# EDMA3CC register map
Vendor: Texas Instruments
Peripheral module from a debugger description file (folder am437x).
Registers are 32-bit, access per field, no defined reset value unless marked. A register's access mark holds for its fields unless they carry their own. Offsets are as the file gives them; lines under a group give offsets from that group; [hi:lo] are bit positions; {n}, {i} and the like mark numbered series; 'fields as' and 'values as' point back to an identical list; <NAME> marks a mode.

## EDMA3CC (part 1 of 3)
0x800 MPFAR ro — A CPU write of 1 to the MPFCLR bit in the memory protection fault command register (MPFCR) causes any error conditions stored in MPFAR to be cleared.
  [31:0] FADDR — Fault address. [[br]]This 32 bit read-only status register contains the fault address when a memory protection violation is detected. [[br]]This register can only be cleared via the memory protection fault command register (MPFCR). [[br]]Value 0 to FFFF FFFFh.
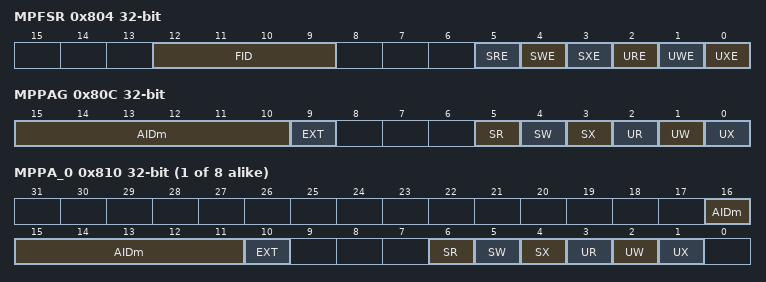
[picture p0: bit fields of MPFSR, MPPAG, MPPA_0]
0x804 MPFSR ro — A CPU write of 1 to the MPFCLR bit in the memory protection fault command register (MPFCR) causes any error conditions stored in MPFSR to be cleared.
  [12:9] FID — Faulted identification. [[br]]FID contains valid information if any of the MP error bits (UXE, UWE, URE, SXE, SWE, SRE) are nonzero (that is, if an error has been detected.) The FID field contains the privilege ID for the specific request/requestor that resulted in an MP error. [[br]]Value 0 to Fh.
  [5] SRE — Supervisor read error.
    1=en_2_0x1 (Supervisor level task attempted to read from a MP page without SR permissions.); 0=en_1_0x0 (No error detected.)
  [4] SWE — Supervisor write error.
    1=en_2_0x1 (Supervisor level task attempted to write to a MP page without SW permissions.); 0=en_1_0x0 (No error detected.)
  [3] SXE — Supervisor execute error.
    1=en_2_0x1 (Supervisor level task attempted to execute from a MP page without SX permissions.); 0=en_1_0x0 (No error detected.)
  [2] URE — User read error.
    1=en_2_0x1 (User level task attempted to read from a MP page without UR permissions.); 0=en_1_0x0 (No error detected.)
  [1] UWE — User write error.
    1=en_2_0x1 (User level task attempted to write to a MP page without UW permissions.); 0=en_1_0x0 (No error detected.)
  [0] UXE — User execute error.
    1=en_2_0x1 (User level task attempted to execute from a MP page without UX permissions.); 0=en_1_0x0 (No error detected.)
0x808 MPFCR
  [0] MPFCLR wo — Fault clear register.
    1=en_2_0x1 (CPU write of 1 to the MPFCLR bit causes any error conditions stored in the memory protection fault address register (MPFAR) and the memory protection fault status register (MPFSR) to be cleared.); 0=en_1_0x0 (CPU write of 0 has no effect.)
0x80C MPPAG
  [15:10] AIDm rw — Allowed ID 'N'
    1=en_2_0x1 (Requests with Privilege ID == N are permitted, if access type is allowed as defined by permission settings (UW, UR, SW, SR).); 0=en_1_0x0 (Requests with Privilege ID == N are not allowed to region M, regardless of permission settings (UW, UR, SW, SR).)
  [9] EXT rw — External Allowed ID.
    1=en_2_0x1 (Requests with Privilege ID >= 6 are permitted, if access type is allowed as defined by permission settings (UW, UR, SW, SR).); 0=en_1_0x0 (Requests with Privilege ID >= 6 are not allowed to region M, regardless of permission settings (UW, UR, SW, SR).)
  [5] SR rw — Supervisor read permission.
    1=en_2_0x1 (Supervisor write accesses are allowed from region M addresses.); 0=en_1_0x0 (Supervisor read accesses are not allowed from region M.)
  [4] SW rw — Supervisor write permission.
    1=en_2_0x1 (Supervisor write accesses are allowed to region N addresses.); 0=en_1_0x0 (Supervisor write accesses are not allowed to region M.)
  [3] SX rw — Supervisor execute permission.
    1=en_2_0x1 (Supervisor execute accesses are allowed from region M addresses.); 0=en_1_0x0 (Supervisor execute accesses are not allowed from region M.)
  [2] UR rw — User read permission.
    1=en_2_0x1 (User read accesses are allowed from region N addresses.); 0=en_1_0x0 (User read accesses are not allowed from region M.)
  [1] UW rw — User write permission.
    1=en_2_0x1 (User write accesses are allowed to region M addresses.); 0=en_1_0x0 (User write accesses are not allowed to region M.)
  [0] UX rw — User execute permission.
    1=en_2_0x1 (User execute accesses are allowed from region M addresses.); 0=en_1_0x0 (User execute accesses are not allowed from region M.)
{0x810+4i} MPPA_{i} (i=0..7)
  [16:11] AIDm rw — Allowed ID 'N'
    values as MPPAG.AIDm
  [10] EXT rw — External Allowed ID.
    values as MPPAG.EXT
  [6] SR rw — Supervisor read permission.
    values as MPPAG.SR
  [5] SW rw — Supervisor write permission.
    values as MPPAG.SW
  [4] SX rw — Supervisor execute permission.
    values as MPPAG.SX
  [3] UR rw — User read permission.
    values as MPPAG.UR
  [2] UW rw — User write permission.
    values as MPPAG.UW
  [1] UX rw — User execute permission.
    values as MPPAG.UX
0x1000 ER ro — All external events are captured in the event register (ER/ERH). The events are latched even when the events are not enabled. If the event bit corresponding to the latched event is enabled (EER.En/EERH.En = 1), then the event is evaluated by the EDMA3CC logic for an associated transfer request submission to the transfer controllers. The event register bits are automatically cleared (ER.En/ERH.En= 0) once the corresponding events are prioritized and serviced. If ER.En/ERH.En are already set and another event is received on the same channel/event, then the corresponding event is latched in the event miss register (EMR.En/EMRH.En), provided that the event was enabled (EER.En/EERH.En = 1). Event n can be cleared by the CPU writing a 1 to corresponding event bit in the event clear register (ECR/ECRH). The setting of an event is a higher priority relative to clear operations (via hardware or software). If set and clear conditions occur concurrently, the set condition wins. If the event was previously set, then EMR/EMRH would be set because an event is lost. If the event was previously clear, then the event remains set and is prioritized for submission to the event queues. The Debug List table provides the type of synchronization events and the EDMA3CC channels associated to each of these external events. This register is part of a set of registers that pertain to the 64 DMA channels. The 64 DMA channels consist of a set of registers (with exception of DMAQNUMn) that each have 64 bits and the bit position of each register matches the DMA channel number. Each register is named with the format reg_name that corresponds to DMA channels 0 through 31 and reg_name_High that corresponds to DMA channels 32 through 64. For example, the event register (ER) corresponds to DMA channel 0 through 31 and the event register high register (ERH) corresponds to DMA channel 32 through 63. The register is typically called the event register. The DMA channel registers are accessible via read/writes to the global address range. They are also accessible via read/writes to the shadow address range. The read/write ability to the registers in the shadow region are controlled by the DMA region access registers (DRAEm/DRAEHm).
  [31:0] En — Event 0 to 31. [[br]]Events 0 to 31 are captured by the EDMA3CC and are latched into ER. [[br]]The events are set (En = 1) even when events are disabled (En = 0 in the event enable register, EER). [[br]]
    1=en_2_0x1 (EDMA3CC event is asserted. Corresponding DMA event is prioritized versus other pending DMA/QDMA events for submission to the EDMA3TC.); 0=en_1_0x0 (EDMA3CC event is not asserted.)
0x1004 ERH ro — All external events are captured in the event register (ER/ERH). The events are latched even when the events are not enabled. If the event bit corresponding to the latched event is enabled (EER.En/EERH.En = 1), then the event is evaluated by the EDMA3CC logic for an associated transfer request submission to the transfer controllers. The event register bits are automatically cleared (ER.En/ERH.En= 0) once the corresponding events are prioritized and serviced. If ER.En/ERH.En are already set and another event is received on the same channel/event, then the corresponding event is latched in the event miss register (EMR.En/EMRH.En), provided that the event was enabled (EER.En/EERH.En = 1). Event n can be cleared by the CPU writing a 1 to corresponding event bit in the event clear register (ECR/ECRH). The setting of an event is a higher priority relative to clear operations (via hardware or software). If set and clear conditions occur concurrently, the set condition wins. If the event was previously set, then EMR/EMRH would be set because an event is lost. If the event was previously clear, then the event remains set and is prioritized for submission to the event queues. The Debug List table provides the type of synchronization events and the EDMA3CC channels associated to each of these external events. This register is part of a set of registers that pertain to the 64 DMA channels. The 64 DMA channels consist of a set of registers (with exception of DMAQNUMn) that each have 64 bits and the bit position of each register matches the DMA channel number. Each register is named with the format reg_name that corresponds to DMA channels 0 through 31 and reg_name_High that corresponds to DMA channels 32 through 64. For example, the event register (ER) corresponds to DMA channel 0 through 31 and the event register high register (ERH) corresponds to DMA channel 32 through 63. The register is typically called the event register. The DMA channel registers are accessible via read/writes to the global address range. They are also accessible via read/writes to the shadow address range. The read/write ability to the registers in the shadow region are controlled by the DMA region access registers (DRAEm/DRAEHm).
  [31:0] En — Event 32 to 63. [[br]]Events 32 to 63 are captured by the EDMA3CC and are latched into ERH. [[br]]The events are set (En = 1) even when events are disabled (En = 0 in the event enable register high, EERH). [[br]]
    values as ER.En
0x1008 ECR wo — Once an event has been posted in the event registers (ER/ERH), the event is cleared in two ways. If the event is enabled in the event enable register (EER/EERH) and the EDMA3CC submits a transfer request for the event to the EDMA3TC, it clears the corresponding event bit in the event register. If the event is disabled in the event enable register (EER/EERH), the CPU can clear the event by way of the event clear registers (ECR/ECRH). Writing a 1 to any of the bits clears the corresponding event; writing a 0 has no effect. Once an event bit is set in the event register, it remains set until EDMA3CC submits a transfer request for that event or the CPU clears the event by setting the corresponding bit in ECR/ECRH. This register is part of a set of registers that pertain to the 64 DMA channels. The 64 DMA channels consist of a set of registers (with exception of DMAQNUMn) that each have 64 bits and the bit position of each register matches the DMA channel number. Each register is named with the format reg_name that corresponds to DMA channels 0 through 31 and reg_name_High that corresponds to DMA channels 32 through 64. For example, the event register (ER) corresponds to DMA channel 0 through 31 and the event register high register (ERH) corresponds to DMA channel 32 through 63. The register is typically called the event register. The DMA channel registers are accessible via read/writes to the global address range. They are also accessible via read/writes to the shadow address range. The read/write ability to the registers in the shadow region are controlled by the DMA region access registers (DRAEm/DRAEHm).
  [31:0] En — Event clear for event 0 to 31. [[br]]Any of the event bits in ECR is set to clear the event (En) in the event register (ER). [[br]]A write of 0 has no effect. [[br]]
    1=en_2_0x1 (EDMA3CC event is cleared in the event register (ER).); 0=en_1_0x0 (No effect.)
0x100C ECRH wo — Once an event has been posted in the event registers (ER/ERH), the event is cleared in two ways. If the event is enabled in the event enable register (EER/EERH) and the EDMA3CC submits a transfer request for the event to the EDMA3TC, it clears the corresponding event bit in the event register. If the event is disabled in the event enable register (EER/EERH), the CPU can clear the event by way of the event clear registers (ECR/ECRH). Writing a 1 to any of the bits clears the corresponding event; writing a 0 has no effect. Once an event bit is set in the event register, it remains set until EDMA3CC submits a transfer request for that event or the CPU clears the event by setting the corresponding bit in ECR/ECRH. This register is part of a set of registers that pertain to the 64 DMA channels. The 64 DMA channels consist of a set of registers (with exception of DMAQNUMn) that each have 64 bits and the bit position of each register matches the DMA channel number. Each register is named with the format reg_name that corresponds to DMA channels 0 through 31 and reg_name_High that corresponds to DMA channels 32 through 64. For example, the event register (ER) corresponds to DMA channel 0 through 31 and the event register high register (ERH) corresponds to DMA channel 32 through 63. The register is typically called the event register. The DMA channel registers are accessible via read/writes to the global address range. They are also accessible via read/writes to the shadow address range. The read/write ability to the registers in the shadow region are controlled by the DMA region access registers (DRAEm/DRAEHm).
  [31:0] En — Event clear for event 32 to 63. [[br]]Any of the event bits in ECRH are set to clear the event (En) in the event register high (ERH). [[br]]A write of 0 has no effect. [[br]]
    1=en_2_0x1 (EDMA3CC event is cleared in the event register high (ERH).); 0=en_1_0x0 (No effect.)
0x1010 ESR rw — The event set registers (ESR/ESRH) allow the CPU (EDMA3 programmers) to manually set events to initiate DMA transfer requests. CPU writes of 1 to any event set register (En) bits set the corresponding bits in the registers. The set event is evaluated by the EDMA3CC logic for an associated transfer request submission to the transfer controllers. Writing a 0 has no effect. The event set registers operate independent of the event registers (ER/ERH), and a write of 1 is always considered a valid event regardless of whether the event is enabled (the corresponding event bits are set or cleared in EER.En/EERH.En). Once the event is set in the event set registers, it cannot be cleared by CPU writes, in other words, the event clear registers (ECR/ECRH) have no effect on the state of ESR/ESRH. The bits will only be cleared once the transfer request corresponding to the event has been submitted to the transfer controller. The setting of an event is a higher priority relative to clear operations (via hardware). If set and clear conditions occur concurrently, the set condition wins. If the event was previously set, then EMR/EMRH would be set because an event is lost. If the event was previously clear, then the event remains set and is prioritized for submission to the event queues. Manually-triggered transfers via writes to ESR/ESRH allow the CPU to submit DMA requests in the system, these are relevant for memory-to-memory transfer scenarios. If the ESR.En/ESRH.En bit is already set and another CPU write of 1 is attempted to the same bit, then the corresponding event is latched in the event missed registers (EMR.En/EMRH.En = 1). This register is part of a set of registers that pertain to the 64 DMA channels. The 64 DMA channels consist of a set of registers (with exception of DMAQNUMn) that each have 64 bits and the bit position of each register matches the DMA channel number. Each register is named with the format reg_name that corresponds to DMA channels 0 through 31 and reg_name_High that corresponds to DMA channels 32 through 64. For example, the event register (ER) corresponds to DMA channel 0 through 31 and the event register high register (ERH) corresponds to DMA channel 32 through 63. The register is typically called the event register. The DMA channel registers are accessible via read/writes to the global address range. They are also accessible via read/writes to the shadow address range. The read/write ability to the registers in the shadow region are controlled by the DMA region access registers (DRAEm/DRAEHm).
  [31:0] En — Event set for event 0 to 31.
    1=en_2_0x1 (Corresponding DMA event is prioritized versus other pending DMA/QDMA events for submission to the EDMA3TC.); 0=en_1_0x0 (No effect.)
0x1014 ESRH rw — The event set registers (ESR/ESRH) allow the CPU (EDMA3 programmers) to manually set events to initiate DMA transfer requests. CPU writes of 1 to any event set register (En) bits set the corresponding bits in the registers. The set event is evaluated by the EDMA3CC logic for an associated transfer request submission to the transfer controllers. Writing a 0 has no effect. The event set registers operate independent of the event registers (ER/ERH), and a write of 1 is always considered a valid event regardless of whether the event is enabled (the corresponding event bits are set or cleared in EER.En/EERH.En). Once the event is set in the event set registers, it cannot be cleared by CPU writes, in other words, the event clear registers (ECR/ECRH) have no effect on the state of ESR/ESRH. The bits will only be cleared once the transfer request corresponding to the event has been submitted to the transfer controller. The setting of an event is a higher priority relative to clear operations (via hardware). If set and clear conditions occur concurrently, the set condition wins. If the event was previously set, then EMR/EMRH would be set because an event is lost. If the event was previously clear, then the event remains set and is prioritized for submission to the event queues. Manually-triggered transfers via writes to ESR/ESRH allow the CPU to submit DMA requests in the system, these are relevant for memory-to-memory transfer scenarios. If the ESR.En/ESRH.En bit is already set and another CPU write of 1 is attempted to the same bit, then the corresponding event is latched in the event missed registers (EMR.En/EMRH.En = 1). This register is part of a set of registers that pertain to the 64 DMA channels. The 64 DMA channels consist of a set of registers (with exception of DMAQNUMn) that each have 64 bits and the bit position of each register matches the DMA channel number. Each register is named with the format reg_name that corresponds to DMA channels 0 through 31 and reg_name_High that corresponds to DMA channels 32 through 64. For example, the event register (ER) corresponds to DMA channel 0 through 31 and the event register high register (ERH) corresponds to DMA channel 32 through 63. The register is typically called the event register. The DMA channel registers are accessible via read/writes to the global address range. They are also accessible via read/writes to the shadow address range. The read/write ability to the registers in the shadow region are controlled by the DMA region access registers (DRAEm/DRAEHm).
  [31:0] En — Event set for event 32 to 63.
    values as ESR.En
0x1018 CER ro — When the OPTIONS parameter for a PaRAM entry is programmed to returned a chained completion code (ITCCHEN = 1 and/or TCCHEN = 1), then the value dictated by the TCC[5:0] (also programmed in OPT) forces the corresponding event bit to be set in the chained event registers (CER/CERH). The set chained event is evaluated by the EDMA3CC logic for an associated transfer request submission to the transfer controllers. This results in a chained-triggered transfer. The chained event registers do not have any enables. The generation of a chained event is essentially enabled by the PaRAM entry that has been configured for intermediate and/or final chaining on transfer completion. The En bit is set (regardless of the state of EER.En/EERH.En) when a chained completion code is returned from one of the transfer controllers or is generated by the EDMA3CC via the early completion path. The bits in the chained event register are cleared when the corresponding events are prioritized and serviced. If the En bit is already set and another chaining completion code is return for the same event, then the corresponding event is latched in the event missed registers (EMR.En/EMRH.En= 1). The setting of an event is a higher priority relative to clear operations (via hardware). If set and clear conditions occur concurrently, the set condition wins. If the event was previously set, then EMR/EMRH would be set because an event is lost. If the event was previously clear, then the event remains set and is prioritized for submission to the event queues. This register is part of a set of registers that pertain to the 64 DMA channels. The 64 DMA channels consist of a set of registers (with exception of DMAQNUMn) that each have 64 bits and the bit position of each register matches the DMA channel number. Each register is named with the format reg_name that corresponds to DMA channels 0 through 31 and reg_name_High that corresponds to DMA channels 32 through 64. For example, the event register (ER) corresponds to DMA channel 0 through 31 and the event register high register (ERH) corresponds to DMA channel 32 through 63. The register is typically called the event register. The DMA channel registers are accessible via read/writes to the global address range. They are also accessible via read/writes to the shadow address range. The read/write ability to the registers in the shadow region are controlled by the DMA region access registers (DRAEm/DRAEHm).
  [31:0] En — Chained event for event 0 to 31.
    values as ESR.En
0x101C CERH ro — When the OPTIONS parameter for a PaRAM entry is programmed to returned a chained completion code (ITCCHEN = 1 and/or TCCHEN = 1), then the value dictated by the TCC[5:0] (also programmed in OPT) forces the corresponding event bit to be set in the chained event registers (CER/CERH). The set chained event is evaluated by the EDMA3CC logic for an associated transfer request submission to the transfer controllers. This results in a chained-triggered transfer. The chained event registers do not have any enables. The generation of a chained event is essentially enabled by the PaRAM entry that has been configured for intermediate and/or final chaining on transfer completion. The En bit is set (regardless of the state of EER.En/EERH.En) when a chained completion code is returned from one of the transfer controllers or is generated by the EDMA3CC via the early completion path. The bits in the chained event register are cleared when the corresponding events are prioritized and serviced. If the En bit is already set and another chaining completion code is return for the same event, then the corresponding event is latched in the event missed registers (EMR.En/EMRH.En= 1). The setting of an event is a higher priority relative to clear operations (via hardware). If set and clear conditions occur concurrently, the set condition wins. If the event was previously set, then EMR/EMRH would be set because an event is lost. If the event was previously clear, then the event remains set and is prioritized for submission to the event queues. This register is part of a set of registers that pertain to the 64 DMA channels. The 64 DMA channels consist of a set of registers (with exception of DMAQNUMn) that each have 64 bits and the bit position of each register matches the DMA channel number. Each register is named with the format reg_name that corresponds to DMA channels 0 through 31 and reg_name_High that corresponds to DMA channels 32 through 64. For example, the event register (ER) corresponds to DMA channel 0 through 31 and the event register high register (ERH) corresponds to DMA channel 32 through 63. The register is typically called the event register. The DMA channel registers are accessible via read/writes to the global address range. They are also accessible via read/writes to the shadow address range. The read/write ability to the registers in the shadow region are controlled by the DMA region access registers (DRAEm/DRAEHm).
  [31:0] En — Chained event set for event 32 to 63.
    values as ESR.En
0x1020 EER ro — The EDMA3CC provides the option of selectively enabling/disabling each event in the event registers (ER/ERH) by using the event enable registers (EER/EERH). If an event bit in EER/EERH is set (using the event enable set registers, EESR/EESRH), it will enable that corresponding event. Alternatively, if an event bit in EER/EERH is cleared (using the event enable clear registers, EECR/EECRH), it will disable the corresponding event. The event registers latch all events that are captured by EDMA3CC, even if the events are disabled (although EDMA3CC does not process it). Enabling an event with a pending event already set in the event registers enables the EDMA3CC to process the already set event like any other new event. The EER/EERH settings do not have any effect on chained events (CER.En/CERH.En= 1) and manually set events (ESR.En/ESRH.En= 1). This register is part of a set of registers that pertain to the 64 DMA channels. The 64 DMA channels consist of a set of registers (with exception of DMAQNUMn) that each have 64 bits and the bit position of each register matches the DMA channel number. Each register is named with the format reg_name that corresponds to DMA channels 0 through 31 and reg_name_High that corresponds to DMA channels 32 through 64. For example, the event register (ER) corresponds to DMA channel 0 through 31 and the event register high register (ERH) corresponds to DMA channel 32 through 63. The register is typically called the event register. The DMA channel registers are accessible via read/writes to the global address range. They are also accessible via read/writes to the shadow address range. The read/write ability to the registers in the shadow region are controlled by the DMA region access registers (DRAEm/DRAEHm).
  [31:0] En — Event enable for events 0 to 31.
    1=en_2_0x1 (Event is enabled. An external event latched in the event register (ER) is evaluated by the EDMA3CC.); 0=en_1_0x0 (Event is not enabled. An external event latched in the event register (ER) is not evaluated by the EDMA3CC.)
0x1024 EERH ro — The EDMA3CC provides the option of selectively enabling/disabling each event in the event registers (ER/ERH) by using the event enable registers (EER/EERH). If an event bit in EER/EERH is set (using the event enable set registers, EESR/EESRH), it will enable that corresponding event. Alternatively, if an event bit in EER/EERH is cleared (using the event enable clear registers, EECR/EECRH), it will disable the corresponding event. The event registers latch all events that are captured by EDMA3CC, even if the events are disabled (although EDMA3CC does not process it). Enabling an event with a pending event already set in the event registers enables the EDMA3CC to process the already set event like any other new event. The EER/EERH settings do not have any effect on chained events (CER.En/CERH.En= 1) and manually set events (ESR.En/ESRH.En= 1). This register is part of a set of registers that pertain to the 64 DMA channels. The 64 DMA channels consist of a set of registers (with exception of DMAQNUMn) that each have 64 bits and the bit position of each register matches the DMA channel number. Each register is named with the format reg_name that corresponds to DMA channels 0 through 31 and reg_name_High that corresponds to DMA channels 32 through 64. For example, the event register (ER) corresponds to DMA channel 0 through 31 and the event register high register (ERH) corresponds to DMA channel 32 through 63. The register is typically called the event register. The DMA channel registers are accessible via read/writes to the global address range. They are also accessible via read/writes to the shadow address range. The read/write ability to the registers in the shadow region are controlled by the DMA region access registers (DRAEm/DRAEHm).
  [31:0] En — Event enable for events 32 to 63.
    1=en_2_0x1 (Event is enabled. An external event latched in the event register high (ERH) is evaluated by the EDMA3CC.); 0=en_1_0x0 (Event is not enabled. An external event latched in the event register high (ERH) is not evaluated by the EDMA3CC.)
0x1028 EECR wo — The event enable registers (EER/EERH) cannot be modified by directly writing to them. The intent is to ease the software burden for the case where multiple tasks are attempting to simultaneously modify these registers. The event enable clear registers (EECR/EECRH) are used to disable events. Writes of 1 to the bits in EECR/EECRH clear the corresponding event bits in EER/EERH; writes of 0 have no effect. This register is part of a set of registers that pertain to the 64 DMA channels. The 64 DMA channels consist of a set of registers (with exception of DMAQNUMn) that each have 64 bits and the bit position of each register matches the DMA channel number. Each register is named with the format reg_name that corresponds to DMA channels 0 through 31 and reg_name_High that corresponds to DMA channels 32 through 64. For example, the event register (ER) corresponds to DMA channel 0 through 31 and the event register high register (ERH) corresponds to DMA channel 32 through 63. The register is typically called the event register. The DMA channel registers are accessible via read/writes to the global address range. They are also accessible via read/writes to the shadow address range. The read/write ability to the registers in the shadow region are controlled by the DMA region access registers (DRAEm/DRAEHm).
  [31:0] En — Event enable clear for events 0 to 31.
    1=en_2_0x1 (Event is disabled. Corresponding bit in the event enable register (EER) is cleared (En = 0).); 0=en_1_0x0 (No effect.)
